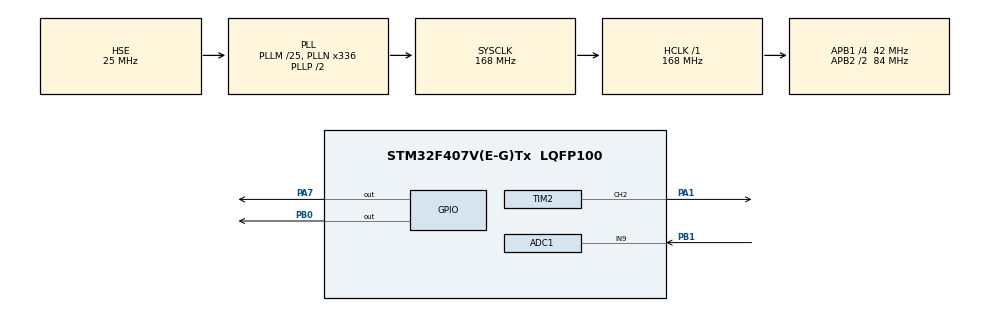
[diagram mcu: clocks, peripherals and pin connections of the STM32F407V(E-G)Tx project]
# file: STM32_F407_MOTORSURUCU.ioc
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ADC1.Channel-0\#ChannelRegularConversion=ADC_CHANNEL_9
ADC1.ContinuousConvMode=ENABLE
ADC1.NbrOfConversionFlag=1
ADC1.Rank-0\#ChannelRegularConversion=1
ADC1.SamplingTime-0\#ChannelRegularConversion=ADC_SAMPLETIME_3CYCLES
ADC1.master=1
Mcu.Family=STM32F4
Mcu.Name=STM32F407V(E-G)Tx
Mcu.Package=LQFP100
NVIC.PriorityGroup=NVIC_PRIORITYGROUP_4
PA1.Signal=S_TIM2_CH2
PA13.Mode=Serial_Wire
PA13.Signal=SYS_JTMS-SWDIO
PA14.Mode=Serial_Wire
PA14.Signal=SYS_JTCK-SWCLK
PA7.Signal=GPIO_Output
PB0.Signal=GPIO_Output
PB1.Signal=ADCx_IN9
PH0-OSC_IN.Mode=HSE-External-Oscillator
PH0-OSC_IN.Signal=RCC_OSC_IN
PH1-OSC_OUT.Mode=HSE-External-Oscillator
PH1-OSC_OUT.Signal=RCC_OSC_OUT
ProjectManager.HeapSize=0x200
ProjectManager.StackSize=0x400
ProjectManager.TargetToolchain=STM32CubeIDE
RCC.48MHZClocksFreq_Value=84000000
RCC.AHBFreq_Value=168000000
RCC.APB1CLKDivider=RCC_HCLK_DIV4
RCC.APB1Freq_Value=42000000
RCC.APB1TimFreq_Value=84000000
RCC.APB2CLKDivider=RCC_HCLK_DIV2
RCC.APB2Freq_Value=84000000
RCC.APB2TimFreq_Value=168000000
RCC.CortexFreq_Value=168000000
RCC.HCLKFreq_Value=168000000
RCC.HSE_VALUE=25000000
RCC.HSI_VALUE=16000000
RCC.LSE_VALUE=32768
RCC.PLLM=25
RCC.PLLN=336
RCC.PLLSourceVirtual=RCC_PLLSOURCE_HSE
RCC.SYSCLKFreq_VALUE=168000000
RCC.SYSCLKSource=RCC_SYSCLKSOURCE_PLLCLK
RCC.VCOOutputFreq_Value=336000000
SH.ADCx_IN9.0=ADC1_IN9,IN9
SH.S_TIM2_CH2.0=TIM2_CH2,PWM Generation2 CH2
TIM2.Channel-PWM\ Generation2\ CH2=TIM_CHANNEL_2
TIM2.Period=65535-1
TIM2.Prescaler=168-1
VP_TIM2_VS_ClockSourceINT.Mode=Internal
board=custom

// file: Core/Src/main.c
/* USER CODE BEGIN Header */
/**
  ******************************************************************************
  * @file           : main.c
  * @brief          : Main program body
  ******************************************************************************
  * @attention
  *
  * Copyright (c) 2023 STMicroelectronics.
  * All rights reserved.
  *
  * This software is licensed under terms that can be found in the LICENSE file
  * in the root directory of this software component.
  * If no LICENSE file comes with this software, it is provided AS-IS.
  *
  ******************************************************************************
  */
/* USER CODE END Header */
#include "main.h"

ADC_HandleTypeDef hadc1;

TIM_HandleTypeDef htim2;

void SystemClock_Config(void);
static void MX_GPIO_Init(void);
static void MX_ADC1_Init(void);
static void MX_TIM2_Init(void);

int main(void)
{

  /* MCU Configuration--------------------------------------------------------*/

  /* Reset of all peripherals, Initializes the Flash interface and the Systick. */
  HAL_Init();

  /* Configure the system clock */
  SystemClock_Config();

  /* Initialize all configured peripherals */
  MX_GPIO_Init();
  MX_ADC1_Init();
  MX_TIM2_Init();
  /* USER CODE BEGIN 2 */
  HAL_ADC_Start(&hadc1);  //PB1
  HAL_TIM_PWM_Start(&htim2, TIM_CHANNEL_2); //PA1 TIM2 CH2
  uint16_t readValue;
  int speed;
  HAL_GPIO_WritePin(GPIOA, GPIO_PIN_7, 0);
  HAL_GPIO_WritePin(GPIOB, GPIO_PIN_1, 0);

  /* USER CODE END 2 */

  /* Infinite loop */
  /* USER CODE BEGIN WHILE */
  while (1)
  {
	    HAL_ADC_PollForConversion(&hadc1,1000);
	    readValue = HAL_ADC_GetValue(&hadc1);

	    HAL_GPIO_WritePin(GPIOA, GPIO_PIN_7, 1);
	    HAL_GPIO_WritePin(GPIOB, GPIO_PIN_0, 1);
	    speed = (readValue - 1790) * (-1) / 3;

	    __HAL_TIM_SET_COMPARE(&htim2,TIM_CHANNEL_2, speed);
	    HAL_Delay(50);
    /* USER CODE END WHILE */

  }
}

void SystemClock_Config(void)
{
  RCC_OscInitTypeDef RCC_OscInitStruct = {0};
  RCC_ClkInitTypeDef RCC_ClkInitStruct = {0};

  /** Configure the main internal regulator output voltage
  */
  __HAL_RCC_PWR_CLK_ENABLE();
  __HAL_PWR_VOLTAGESCALING_CONFIG(PWR_REGULATOR_VOLTAGE_SCALE1);

  /** Initializes the RCC Oscillators according to the specified parameters
  * in the RCC_OscInitTypeDef structure.
  */
  RCC_OscInitStruct.OscillatorType = RCC_OSCILLATORTYPE_HSE;
  RCC_OscInitStruct.HSEState = RCC_HSE_ON;
  RCC_OscInitStruct.PLL.PLLState = RCC_PLL_ON;
  RCC_OscInitStruct.PLL.PLLSource = RCC_PLLSOURCE_HSE;
  RCC_OscInitStruct.PLL.PLLM = 25;
  RCC_OscInitStruct.PLL.PLLN = 336;
  RCC_OscInitStruct.PLL.PLLP = RCC_PLLP_DIV2;
  RCC_OscInitStruct.PLL.PLLQ = 4;
  if (HAL_RCC_OscConfig(&RCC_OscInitStruct) != HAL_OK)
  {
    Error_Handler();
  }

  /** Initializes the CPU, AHB and APB buses clocks
  */
  RCC_ClkInitStruct.ClockType = RCC_CLOCKTYPE_HCLK|RCC_CLOCKTYPE_SYSCLK
                              |RCC_CLOCKTYPE_PCLK1|RCC_CLOCKTYPE_PCLK2;
  RCC_ClkInitStruct.SYSCLKSource = RCC_SYSCLKSOURCE_PLLCLK;
  RCC_ClkInitStruct.AHBCLKDivider = RCC_SYSCLK_DIV1;
  RCC_ClkInitStruct.APB1CLKDivider = RCC_HCLK_DIV4;
  RCC_ClkInitStruct.APB2CLKDivider = RCC_HCLK_DIV2;

  if (HAL_RCC_ClockConfig(&RCC_ClkInitStruct, FLASH_LATENCY_5) != HAL_OK)
  {
    Error_Handler();
  }
}

static void MX_ADC1_Init(void)
{

  ADC_ChannelConfTypeDef sConfig = {0};

  /** Configure the global features of the ADC (Clock, Resolution, Data Alignment and number of conversion)
  */
  hadc1.Instance = ADC1;
  hadc1.Init.ClockPrescaler = ADC_CLOCK_SYNC_PCLK_DIV4;
  hadc1.Init.Resolution = ADC_RESOLUTION_12B;
  hadc1.Init.ScanConvMode = DISABLE;
  hadc1.Init.ContinuousConvMode = ENABLE;
  hadc1.Init.DiscontinuousConvMode = DISABLE;
  hadc1.Init.ExternalTrigConvEdge = ADC_EXTERNALTRIGCONVEDGE_NONE;
  hadc1.Init.ExternalTrigConv = ADC_SOFTWARE_START;
  hadc1.Init.DataAlign = ADC_DATAALIGN_RIGHT;
  hadc1.Init.NbrOfConversion = 1;
  hadc1.Init.DMAContinuousRequests = DISABLE;
  hadc1.Init.EOCSelection = ADC_EOC_SINGLE_CONV;
  if (HAL_ADC_Init(&hadc1) != HAL_OK)
  {
    Error_Handler();
  }

  /** Configure for the selected ADC regular channel its corresponding rank in the sequencer and its sample time.
  */
  sConfig.Channel = ADC_CHANNEL_9;
  sConfig.Rank = 1;
  sConfig.SamplingTime = ADC_SAMPLETIME_3CYCLES;
  if (HAL_ADC_ConfigChannel(&hadc1, &sConfig) != HAL_OK)
  {
    Error_Handler();
  }

}

static void MX_TIM2_Init(void)
{

  TIM_ClockConfigTypeDef sClockSourceConfig = {0};
  TIM_MasterConfigTypeDef sMasterConfig = {0};
  TIM_OC_InitTypeDef sConfigOC = {0};

  htim2.Instance = TIM2;
  htim2.Init.Prescaler = 168-1;
  htim2.Init.CounterMode = TIM_COUNTERMODE_UP;
  htim2.Init.Period = 65535-1;
  htim2.Init.ClockDivision = TIM_CLOCKDIVISION_DIV1;
  htim2.Init.AutoReloadPreload = TIM_AUTORELOAD_PRELOAD_DISABLE;
  if (HAL_TIM_Base_Init(&htim2) != HAL_OK)
  {
    Error_Handler();
  }
  sClockSourceConfig.ClockSource = TIM_CLOCKSOURCE_INTERNAL;
  if (HAL_TIM_ConfigClockSource(&htim2, &sClockSourceConfig) != HAL_OK)
  {
    Error_Handler();
  }
  if (HAL_TIM_PWM_Init(&htim2) != HAL_OK)
  {
    Error_Handler();
  }
  sMasterConfig.MasterOutputTrigger = TIM_TRGO_RESET;
  sMasterConfig.MasterSlaveMode = TIM_MASTERSLAVEMODE_DISABLE;
  if (HAL_TIMEx_MasterConfigSynchronization(&htim2, &sMasterConfig) != HAL_OK)
  {
    Error_Handler();
  }
  sConfigOC.OCMode = TIM_OCMODE_PWM1;
  sConfigOC.Pulse = 0;
  sConfigOC.OCPolarity = TIM_OCPOLARITY_HIGH;
  sConfigOC.OCFastMode = TIM_OCFAST_DISABLE;
  if (HAL_TIM_PWM_ConfigChannel(&htim2, &sConfigOC, TIM_CHANNEL_2) != HAL_OK)
  {
    Error_Handler();
  }
  HAL_TIM_MspPostInit(&htim2);

}

static void MX_GPIO_Init(void)
{
  GPIO_InitTypeDef GPIO_InitStruct = {0};

  /* GPIO Ports Clock Enable */
  __HAL_RCC_GPIOH_CLK_ENABLE();
  __HAL_RCC_GPIOA_CLK_ENABLE();
  __HAL_RCC_GPIOB_CLK_ENABLE();

  /*Configure GPIO pin Output Level */
  HAL_GPIO_WritePin(GPIOA, GPIO_PIN_7, GPIO_PIN_RESET);

  /*Configure GPIO pin Output Level */
  HAL_GPIO_WritePin(GPIOB, GPIO_PIN_0, GPIO_PIN_RESET);

  /*Configure GPIO pin : PA7 */
  GPIO_InitStruct.Pin = GPIO_PIN_7;
  GPIO_InitStruct.Mode = GPIO_MODE_OUTPUT_PP;
  GPIO_InitStruct.Pull = GPIO_NOPULL;
  GPIO_InitStruct.Speed = GPIO_SPEED_FREQ_LOW;
  HAL_GPIO_Init(GPIOA, &GPIO_InitStruct);

  /*Configure GPIO pin : PB0 */
  GPIO_InitStruct.Pin = GPIO_PIN_0;
  GPIO_InitStruct.Mode = GPIO_MODE_OUTPUT_PP;
  GPIO_InitStruct.Pull = GPIO_NOPULL;
  GPIO_InitStruct.Speed = GPIO_SPEED_FREQ_LOW;
  HAL_GPIO_Init(GPIOB, &GPIO_InitStruct);

}

void Error_Handler(void)
{
  __disable_irq();
  while (1)
  {
  }
}
